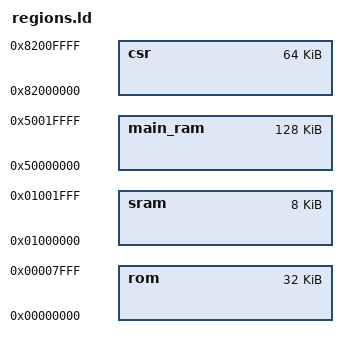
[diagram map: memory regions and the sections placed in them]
MEMORY {
	rom : ORIGIN = 0x00000000, LENGTH = 0x00008000
	sram : ORIGIN = 0x01000000, LENGTH = 0x00002000
	main_ram : ORIGIN = 0x50000000, LENGTH = 0x00020000
	csr : ORIGIN = 0x82000000, LENGTH = 0x00010000
}
